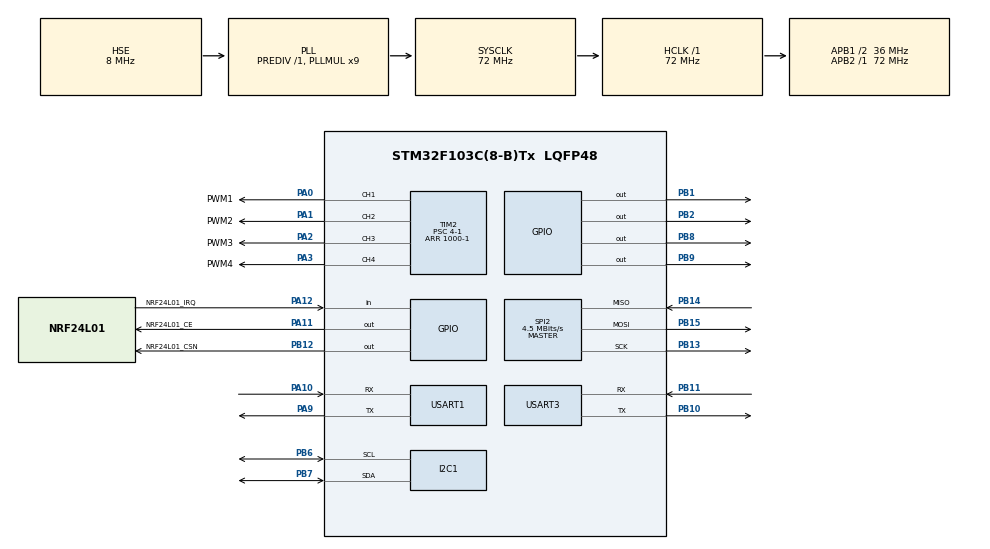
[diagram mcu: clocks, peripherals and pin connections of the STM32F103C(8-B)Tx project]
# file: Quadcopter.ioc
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FREERTOS.HEAP_NUMBER=4
FREERTOS.Tasks01=defaultTask,24,128,StartDefaultTask,Default,NULL,Dynamic,NULL,NULL;LEDTask,8,128,PilotLED,As weak,NULL,Dynamic,NULL,NULL;MPU6050Task,24,128,MpuGetData,As weak,NULL,Dynamic,NULL,NULL;ANOTask,17,128,ANONRFCheckEvent,As weak,NULL,Dynamic,NULL,NULL;NRFDATAAnl,24,128,NRFConnect,As weak,NULL,Dynamic,NULL,NULL
FREERTOS.configTOTAL_HEAP_SIZE=5000
Mcu.Family=STM32F1
Mcu.Name=STM32F103C(8-B)Tx
Mcu.Package=LQFP48
NVIC.PriorityGroup=NVIC_PRIORITYGROUP_4
PA0-WKUP.GPIO_Label=PWM1
PA0-WKUP.Signal=S_TIM2_CH1_ETR
PA1.GPIO_Label=PWM2
PA1.Signal=S_TIM2_CH2
PA10.Mode=Asynchronous
PA10.Signal=USART1_RX
PA11.GPIO_Label=NRF24L01_CE
PA11.PinState=GPIO_PIN_SET
PA11.Signal=GPIO_Output
PA12.GPIO_Label=NRF24L01_IRQ
PA12.GPIO_PuPd=GPIO_PULLUP
PA12.Signal=GPIO_Input
PA13.Mode=Serial_Wire
PA13.Signal=SYS_JTMS-SWDIO
PA14.Mode=Serial_Wire
PA14.Signal=SYS_JTCK-SWCLK
PA2.GPIO_Label=PWM3
PA2.Signal=S_TIM2_CH3
PA3.GPIO_Label=PWM4
PA3.Signal=S_TIM2_CH4
PA9.Mode=Asynchronous
PA9.Signal=USART1_TX
PB1.Signal=GPIO_Output
PB10.Mode=Asynchronous
PB10.Signal=USART3_TX
PB11.Mode=Asynchronous
PB11.Signal=USART3_RX
PB12.GPIO_Label=NRF24L01_CSN
PB12.PinState=GPIO_PIN_SET
PB12.Signal=GPIO_Output
PB13.Mode=Full_Duplex_Master
PB13.Signal=SPI2_SCK
PB14.Mode=Full_Duplex_Master
PB14.Signal=SPI2_MISO
PB15.Mode=Full_Duplex_Master
PB15.Signal=SPI2_MOSI
PB2.Signal=GPIO_Output
PB6.Mode=I2C
PB6.Signal=I2C1_SCL
PB7.Mode=I2C
PB7.Signal=I2C1_SDA
PB8.Signal=GPIO_Output
PB9.Signal=GPIO_Output
PD0-OSC_IN.Mode=HSE-External-Oscillator
PD0-OSC_IN.Signal=RCC_OSC_IN
PD1-OSC_OUT.Mode=HSE-External-Oscillator
PD1-OSC_OUT.Signal=RCC_OSC_OUT
ProjectManager.HeapSize=0x200
ProjectManager.StackSize=0x400
ProjectManager.TargetToolchain=MDK-ARM V5.32
RCC.AHBFreq_Value=72000000
RCC.APB1CLKDivider=RCC_HCLK_DIV2
RCC.APB1Freq_Value=36000000
RCC.APB1TimFreq_Value=72000000
RCC.APB2Freq_Value=72000000
RCC.APB2TimFreq_Value=72000000
RCC.HCLKFreq_Value=72000000
RCC.PLLMUL=RCC_PLL_MUL9
RCC.PLLSourceVirtual=RCC_PLLSOURCE_HSE
RCC.SYSCLKFreq_VALUE=72000000
RCC.SYSCLKSource=RCC_SYSCLKSOURCE_PLLCLK
RCC.USBFreq_Value=72000000
SH.S_TIM2_CH1_ETR.0=TIM2_CH1,PWM Generation1 CH1
SH.S_TIM2_CH2.0=TIM2_CH2,PWM Generation2 CH2
SH.S_TIM2_CH3.0=TIM2_CH3,PWM Generation3 CH3
SH.S_TIM2_CH4.0=TIM2_CH4,PWM Generation4 CH4
SPI2.BaudRatePrescaler=SPI_BAUDRATEPRESCALER_8
SPI2.CalculateBaudRate=4.5 MBits/s
SPI2.Direction=SPI_DIRECTION_2LINES
SPI2.Mode=SPI_MODE_MASTER
SPI2.VirtualType=VM_MASTER
TIM2.AutoReloadPreload=TIM_AUTORELOAD_PRELOAD_ENABLE
TIM2.Channel-PWM\ Generation1\ CH1=TIM_CHANNEL_1
TIM2.Channel-PWM\ Generation2\ CH2=TIM_CHANNEL_2
TIM2.Channel-PWM\ Generation3\ CH3=TIM_CHANNEL_3
TIM2.Channel-PWM\ Generation4\ CH4=TIM_CHANNEL_4
TIM2.Period=1000-1
TIM2.Prescaler=4-1
USART1.VirtualMode=VM_ASYNC
USART3.VirtualMode=VM_ASYNC
VP_FREERTOS_VS_CMSIS_V2.Mode=CMSIS_V2
board=custom

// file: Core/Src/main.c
/* USER CODE BEGIN Header */
/**
 ******************************************************************************
 * @file           : main.c
 * @brief          : Main program body
 ******************************************************************************
 * @attention
 *
 * Copyright (c) 2024 STMicroelectronics.
 * All rights reserved.
 *
 * This software is licensed under terms that can be found in the LICENSE file
 * in the root directory of this software component.
 * If no LICENSE file comes with this software, it is provided AS-IS.
 *
 ******************************************************************************
 */
/* USER CODE END Header */
#include "main.h"
#include "cmsis_os.h"
#include "i2c.h"
#include "spi.h"
#include "tim.h"
#include "usart.h"
#include "gpio.h"

/* USER CODE BEGIN Includes */

#include "NRF24L01/nrf24l01.h"
#include "MPU6050/MPU6050.h"
#include "stdio.h"
/* USER CODE END Includes */

void SystemClock_Config(void);
void MX_FREERTOS_Init(void);

int main(void)
{

  /* MCU Configuration--------------------------------------------------------*/

  /* Reset of all peripherals, Initializes the Flash interface and the Systick. */
  HAL_Init();

  /* Configure the system clock */
  SystemClock_Config();

  /* Initialize all configured peripherals */
  MX_GPIO_Init();
  MX_I2C1_Init();
  MX_USART3_UART_Init();
  MX_SPI2_Init();
  MX_TIM2_Init();
  MX_USART1_UART_Init();
  /* USER CODE BEGIN 2 */
  // HAL_UART_Transmit(&huart3,(uint8_t*)"mpuinit faied",14,HAL_MAX_DELAY);
  if (MPU6050_Init(Sensor_I2C2_Serch()) == -1)
  {
    printf("mpuinit faied\n");
  }
  NRF24L01_init();
  /* USER CODE END 2 */

  /* Init scheduler */
  osKernelInitialize();

  /* Call init function for freertos objects (in cmsis_os2.c) */
  MX_FREERTOS_Init();

  /* Start scheduler */
  osKernelStart();

  /* We should never get here as control is now taken by the scheduler */

  /* Infinite loop */
  while (1)
  {

  }
}

void SystemClock_Config(void)
{
  RCC_OscInitTypeDef RCC_OscInitStruct = {0};
  RCC_ClkInitTypeDef RCC_ClkInitStruct = {0};

  /** Initializes the RCC Oscillators according to the specified parameters
  * in the RCC_OscInitTypeDef structure.
  */
  RCC_OscInitStruct.OscillatorType = RCC_OSCILLATORTYPE_HSE;
  RCC_OscInitStruct.HSEState = RCC_HSE_ON;
  RCC_OscInitStruct.HSEPredivValue = RCC_HSE_PREDIV_DIV1;
  RCC_OscInitStruct.HSIState = RCC_HSI_ON;
  RCC_OscInitStruct.PLL.PLLState = RCC_PLL_ON;
  RCC_OscInitStruct.PLL.PLLSource = RCC_PLLSOURCE_HSE;
  RCC_OscInitStruct.PLL.PLLMUL = RCC_PLL_MUL9;
  if (HAL_RCC_OscConfig(&RCC_OscInitStruct) != HAL_OK)
  {
    Error_Handler();
  }

  /** Initializes the CPU, AHB and APB buses clocks
  */
  RCC_ClkInitStruct.ClockType = RCC_CLOCKTYPE_HCLK|RCC_CLOCKTYPE_SYSCLK
                              |RCC_CLOCKTYPE_PCLK1|RCC_CLOCKTYPE_PCLK2;
  RCC_ClkInitStruct.SYSCLKSource = RCC_SYSCLKSOURCE_PLLCLK;
  RCC_ClkInitStruct.AHBCLKDivider = RCC_SYSCLK_DIV1;
  RCC_ClkInitStruct.APB1CLKDivider = RCC_HCLK_DIV2;
  RCC_ClkInitStruct.APB2CLKDivider = RCC_HCLK_DIV1;

  if (HAL_RCC_ClockConfig(&RCC_ClkInitStruct, FLASH_LATENCY_2) != HAL_OK)
  {
    Error_Handler();
  }
}

void Error_Handler(void)
{
  __disable_irq();
  while (1)
  {
  }
}

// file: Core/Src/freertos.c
/* USER CODE BEGIN Header */
/**
 ******************************************************************************
 * File Name          : freertos.c
 * Description        : Code for freertos applications
 ******************************************************************************
 * @attention
 *
 * Copyright (c) 2024 STMicroelectronics.
 * All rights reserved.
 *
 * This software is licensed under terms that can be found in the LICENSE file
 * in the root directory of this software component.
 * If no LICENSE file comes with this software, it is provided AS-IS.
 *
 ******************************************************************************
 */
/* USER CODE END Header */

#include "FreeRTOS.h"
#include "task.h"
#include "main.h"
#include "cmsis_os.h"

/* USER CODE BEGIN Includes */
#include "stdio.h"
/* USER CODE END Includes */

/* Definitions for defaultTask */
osThreadId_t defaultTaskHandle;
const osThreadAttr_t defaultTask_attributes = {
    .name = "defaultTask",
    .stack_size = 128 * 4,
    .priority = (osPriority_t)osPriorityNormal,
};
/* Definitions for LEDTask */
osThreadId_t LEDTaskHandle;
const osThreadAttr_t LEDTask_attributes = {
    .name = "LEDTask",
    .stack_size = 128 * 4,
    .priority = (osPriority_t)osPriorityLow,
};
/* Definitions for MPU6050Task */
osThreadId_t MPU6050TaskHandle;
const osThreadAttr_t MPU6050Task_attributes = {
    .name = "MPU6050Task",
    .stack_size = 128 * 4,
    .priority = (osPriority_t)osPriorityNormal,
};
/* Definitions for ANOTask */
osThreadId_t ANOTaskHandle;
const osThreadAttr_t ANOTask_attributes = {
    .name = "ANOTask",
    .stack_size = 128 * 4,
    .priority = (osPriority_t)osPriorityBelowNormal1,
};
/* Definitions for NRFDATAAnl */
osThreadId_t NRFDATAAnlHandle;
const osThreadAttr_t NRFDATAAnl_attributes = {
    .name = "NRFDATAAnl",
    .stack_size = 128 * 4,
    .priority = (osPriority_t)osPriorityNormal,
};

void StartDefaultTask(void *argument);
void PilotLED(void *argument);
void MpuGetData(void *argument);
void ANONRFCheckEvent(void *argument);
void NRFConnect(void *argument);

void MX_FREERTOS_Init(void); /* (MISRA C 2004 rule 8.1) */

void MX_FREERTOS_Init(void)
{

  /* Create the thread(s) */
  /* creation of defaultTask */
  defaultTaskHandle = osThreadNew(StartDefaultTask, NULL, &defaultTask_attributes);

  /* creation of LEDTask */
  LEDTaskHandle = osThreadNew(PilotLED, NULL, &LEDTask_attributes);

  /* creation of MPU6050Task */
  MPU6050TaskHandle = osThreadNew(MpuGetData, NULL, &MPU6050Task_attributes);

  /* creation of ANOTask */
  ANOTaskHandle = osThreadNew(ANONRFCheckEvent, NULL, &ANOTask_attributes);

  /* creation of NRFDATAAnl */
  NRFDATAAnlHandle = osThreadNew(NRFConnect, NULL, &NRFDATAAnl_attributes);

}
#include "tim.h"
void StartDefaultTask(void *argument)
{
  /* USER CODE BEGIN StartDefaultTask */
  /* Infinite loop */
  for (;;)
  {

    osDelay(10);
  }
  /* USER CODE END StartDefaultTask */
}

__weak void PilotLED(void *argument)
{
  for (;;)
  {
    osDelay(1);
  }
}

__weak void MpuGetData(void *argument)
{
  for (;;)
  {
    osDelay(1);
  }
}

__weak void ANONRFCheckEvent(void *argument)
{
  for (;;)
  {
    osDelay(1);
  }
}

__weak void NRFConnect(void *argument)
{
  for (;;)
  {
    osDelay(1);
  }
}
